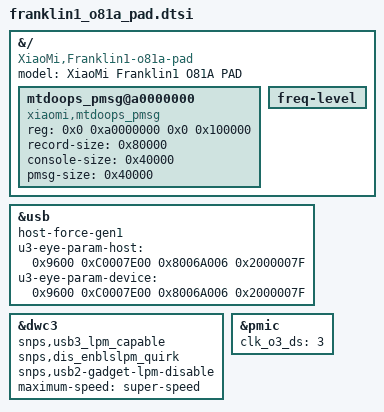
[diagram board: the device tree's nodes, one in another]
// SPDX-License-Identifier: (GPL-2.0+ OR MIT)
/*
 * Copyright 2022 XiaoMi
 */

#include <dt-bindings/interrupt-controller/arm-gic.h>
#include <dt-bindings/xring/platform-specific/asic/memory_layout.h>

&{/} {
    model = "XiaoMi Franklin1 O81A PAD";
    compatible = "XiaoMi,Franklin1-o81a-pad";
    #size-cells = <2>;
    #address-cells = <2>;

    mtdoops_pmsg@a0000000 {
	compatible = "xiaomi,mtdoops_pmsg";
	reg = <0x0 0xa0000000 0x0 0x100000>;
	record-size = <0x80000>;
	console-size = <0x40000>;
	pmsg-size = <0x40000>;
    };

    freq-level {
        status = <0>;
    };
};

&usb {
    //init-state = "peripheral";
    host-force-gen1;
    u3-eye-param-host = <0x9600 0xC0007E00 0x8006A006 0x2000007F>;
    u3-eye-param-device = <0x9600 0xC0007E00 0x8006A006 0x2000007F>;
};

&dwc3 {
    snps,usb3_lpm_capable;
    snps,dis_enblslpm_quirk;
    snps,usb2-gadget-lpm-disable;
    maximum-speed = "super-speed";
};

&pmic {
    clk_o3_ds = <3>;
};
